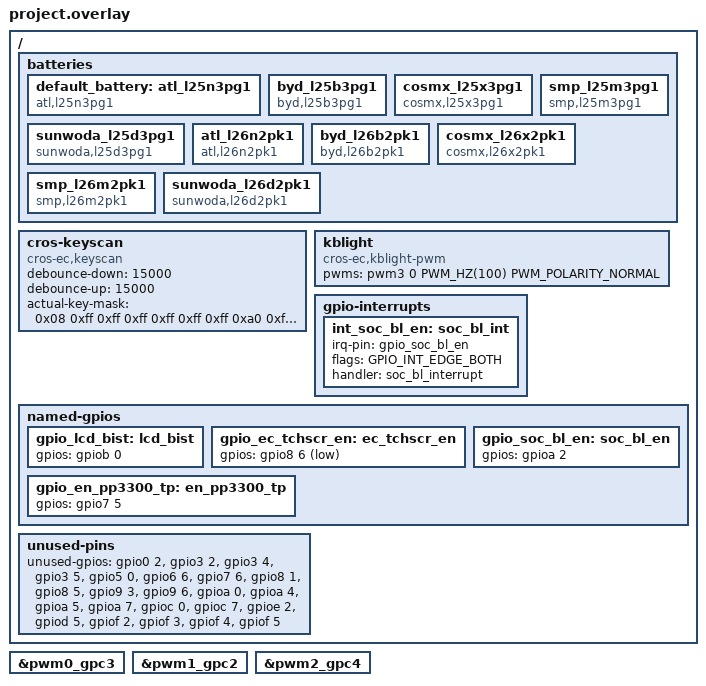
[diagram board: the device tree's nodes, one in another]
/* Copyright 2025 The ChromiumOS Authors
 * Use of this source code is governed by a BSD-style license that can be
 * found in the LICENSE file.
 */

#include <cros/cbi_flash.dtsi>
#include "../npcx_generated.dtsi"
#include "../interrupts.dtsi"
#include "../npcx_common.dtsi"
#include "../npcx_default_gpio_pinctrl.dtsi"
#include "../npcx_keyboard.dtsi"
#include "../npcx_overlay.dtsi"
#include "../npcx_usbc.dtsi"
#include "../power_signal.dtsi"
#include "../usba.dtsi"
#include "cbi.dtsi"
#include "led_pins.dtsi"
#include "led_policy.dtsi"
#include "temp_sensors.dtsi"

/ {
	batteries {
		default_battery: atl_l25n3pg1 {
			compatible = "atl,l25n3pg1", "battery-smart";
		};
		byd_l25b3pg1 {
			compatible = "byd,l25b3pg1", "battery-smart";
		};
		cosmx_l25x3pg1 {
			compatible = "cosmx,l25x3pg1", "battery-smart";
		};
		sunwoda_l25d3pg1 {
			compatible = "sunwoda,l25d3pg1", "battery-smart";
		};
		smp_l25m3pg1 {
			compatible = "smp,l25m3pg1", "battery-smart";
		};
		atl_l26n2pk1 {
			compatible = "atl,l26n2pk1", "battery-smart";
		};
		byd_l26b2pk1 {
			compatible = "byd,l26b2pk1", "battery-smart";
		};
		cosmx_l26x2pk1 {
			compatible = "cosmx,l26x2pk1", "battery-smart";
		};
		smp_l26m2pk1 {
			compatible = "smp,l26m2pk1", "battery-smart";
		};
		sunwoda_l26d2pk1 {
			compatible = "sunwoda,l26d2pk1", "battery-smart";
		};
	};

	cros-keyscan {
		compatible = "cros-ec,keyscan";

		debounce-down = <15000>;
		debounce-up = <15000>;

		actual-key-mask = <
			0x08	/* C0 */
			0xff	/* C1 */
			0xff	/* C2 */
			0xff	/* C3 */
			0xff	/* C4 */
			0xff	/* C5 */
			0xff	/* C6 */
			0xa0	/* C7 */
			0xff	/* C8 */
			0xff	/* C9 */
			0x01	/* C10 */
			0xff	/* C11 */
			0xcf	/* C12 */
			0x40	/* C13 */
			0x0a	/* C14 */
			0x40	/* C15 */
			0x01	/* C16 */
			0xc4	/* C17 */
		>;
	};

	kblight {
		compatible = "cros-ec,kblight-pwm";
		pwms = <&pwm3 0 PWM_HZ(100) PWM_POLARITY_NORMAL>;
	};

	gpio-interrupts {
		/delete-node/ lid-accel;
		/delete-node/ ec-imu;
		/delete-node/ tablet_mode;
		/delete-node/ volume-up;
		/delete-node/ volume-down;

		int_soc_bl_en: soc_bl_int{
			irq-pin = <&gpio_soc_bl_en>;
			flags = <GPIO_INT_EDGE_BOTH>;
			handler = "soc_bl_interrupt";
		};
	};

	named-gpios {
		/delete-node/ en_pp5000_z1;
		/delete-node/ ec_voldn_btn_odl;
		/delete-node/ ec_volup_btn_odl;

		gpio_lcd_bist: lcd_bist {
			gpios = <&gpiob 0 (GPIO_OUTPUT | GPIO_ACTIVE_HIGH | GPIO_OUTPUT_INIT_LOW)>;
		};
		gpio_ec_tchscr_en: ec_tchscr_en {
			gpios = <&gpio8 6 (GPIO_OUTPUT | GPIO_ACTIVE_LOW)>;
		};
		gpio_en_pp3300_tp: en_pp3300_tp {
			gpios = <&gpio7 5 (GPIO_OUTPUT | GPIO_ACTIVE_HIGH | GPIO_OUTPUT_INIT_LOW)>;
		};
		gpio_soc_bl_en: soc_bl_en {
			gpios = <&gpioa 2 (GPIO_INPUT | GPIO_PULL_UP)>;
		};
	};

	unused-pins {
		unused-gpios =
			<&gpio0 2 0>,
			<&gpio3 2 0>,
			<&gpio3 4 0>, /* Reserved for 5V_PWR_MODE */
			<&gpio3 5 0>,
			<&gpio5 0 0>, /* Reserved for PP1800_TCHPAD_EN */
			<&gpio6 6 0>,
			<&gpio7 6 0>,
			<&gpio8 1 0>,
			<&gpio8 5 0>,
			<&gpio9 3 0>,
			<&gpio9 6 0>,
			<&gpioa 0 0>,
			<&gpioa 4 0>,
			<&gpioa 5 0>, /* Reserved for eSIM erasure */
			<&gpioa 7 0>,
			<&gpioc 0 0>,
			<&gpioc 7 0>,
			<&gpioe 2 0>,
			<&gpiod 5 0>,
			<&gpiof 2 0>,
			<&gpiof 3 0>,
			<&gpiof 4 0>,
			<&gpiof 5 0>;
	};
};

&pwm0_gpc3 {
	/delete-property/ drive-open-drain;
};

&pwm1_gpc2 {
	/delete-property/ drive-open-drain;
};

&pwm2_gpc4 {
	/delete-property/ drive-open-drain;
};
